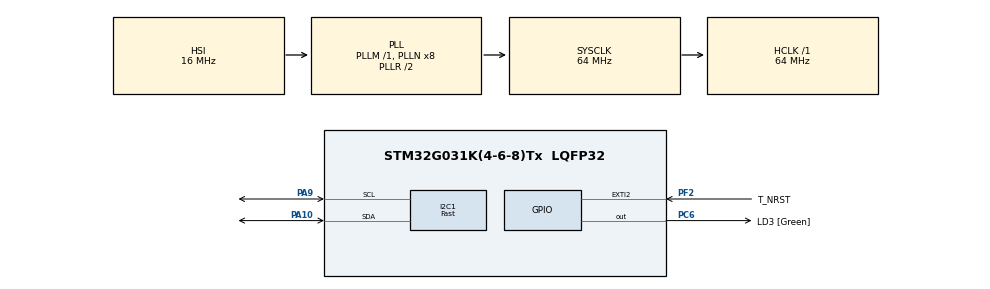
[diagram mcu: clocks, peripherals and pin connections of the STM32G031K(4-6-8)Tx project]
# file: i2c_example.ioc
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I2C1.I2C_Speed_Mode=I2C_Fast
I2C1.OwnAddress=0x45
I2C1.Timing=0x00602173
Mcu.Family=STM32G0
Mcu.Name=STM32G031K(4-6-8)Tx
Mcu.Package=LQFP32
NVIC.I2C1_IRQn=true\:2\:0\:true\:false\:true\:true\:true\:true
PA10.Mode=I2C
PA10.Signal=I2C1_SDA
PA13.GPIO_Label=T_JTMS
PA13.Mode=Serial_Wire
PA13.Signal=SYS_SWDIO
PA14-BOOT0.GPIO_Label=T_JTCK
PA14-BOOT0.Mode=Serial_Wire
PA14-BOOT0.Signal=SYS_SWCLK
PA2.GPIO_Label=T_VCP_TX
PA2.Signal=USART2_TX
PA3.GPIO_Label=T_VCP_RX
PA3.Signal=USART2_RX
PA9.Mode=I2C
PA9.Signal=I2C1_SCL
PC14-OSC32_IN\ (PC14).Mode=LSE-External-Oscillator
PC14-OSC32_IN\ (PC14).Signal=RCC_OSC32_IN
PC15-OSC32_OUT\ (PC15).Mode=LSE-External-Oscillator
PC15-OSC32_OUT\ (PC15).Signal=RCC_OSC32_OUT
PC6.GPIO_Label=LD3 [Green]
PC6.Signal=GPIO_Output
PF2\ -\ NRST.GPIO_Label=T_NRST
PF2\ -\ NRST.Signal=GPXTI2
ProjectManager.HeapSize=0x200
ProjectManager.StackSize=0x400
ProjectManager.TargetToolchain=STM32CubeIDE
RCC.ADCFreq_Value=64000000
RCC.AHBFreq_Value=64000000
RCC.CortexFreq_Value=64000000
RCC.EXTERNAL_CLOCK_VALUE=12288000
RCC.HCLKFreq_Value=64000000
RCC.HSE_VALUE=3000000
RCC.HSI_VALUE=16000000
RCC.SYSCLKFreq_VALUE=64000000
RCC.SYSCLKSource=RCC_SYSCLKSOURCE_PLLCLK
RCC.VCOOutputFreq_Value=128000000
board=NUCLEO-G031K8

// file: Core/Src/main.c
/* USER CODE BEGIN Header */
/**
  ******************************************************************************
  * @file           : main.c
  * @brief          : Main program body
  ******************************************************************************
  * @attention
  *
  * Copyright (c) 2024 STMicroelectronics.
  * All rights reserved.
  *
  * This software is licensed under terms that can be found in the LICENSE file
  * in the root directory of this software component.
  * If no LICENSE file comes with this software, it is provided AS-IS.
  *
  ******************************************************************************
  */
/* USER CODE END Header */
#include "main.h"

/* USER CODE BEGIN Includes */
#include "i2c_slave.h"
/* USER CODE END Includes */

I2C_HandleTypeDef hi2c1;

void SystemClock_Config(void);
static void MX_GPIO_Init(void);
static void MX_I2C1_Init(void);
/* USER CODE BEGIN PFP */
static void led_lights (void);
/* USER CODE END PFP */

int main(void)
{

  /* MCU Configuration--------------------------------------------------------*/

  /* Reset of all peripherals, Initializes the Flash interface and the Systick. */
  HAL_Init();

  /* Configure the system clock */
  SystemClock_Config();

  /* Initialize all configured peripherals */
  MX_GPIO_Init();
  MX_I2C1_Init();
  /* USER CODE BEGIN 2 */
  HAL_I2C_EnableListen_IT (&hi2c1);
  I2C_Setup_Readonly_Register (0, 0x574D44);		// manufacturer ID
  I2C_Setup_Readonly_Register (1, 0x32200001);		// part number
  I2C_Setup_Readonly_Register (2, 0x0001);			// firmware version
  I2C_Setup_Callback_Register (4, led_lights);
  /* USER CODE END 2 */

  /* Infinite loop */
  while (1)
  {

  }
}

void SystemClock_Config(void)
{
  RCC_OscInitTypeDef RCC_OscInitStruct = {0};
  RCC_ClkInitTypeDef RCC_ClkInitStruct = {0};

  /** Configure the main internal regulator output voltage
  */
  HAL_PWREx_ControlVoltageScaling(PWR_REGULATOR_VOLTAGE_SCALE1);

  /** Initializes the RCC Oscillators according to the specified parameters
  * in the RCC_OscInitTypeDef structure.
  */
  RCC_OscInitStruct.OscillatorType = RCC_OSCILLATORTYPE_HSI;
  RCC_OscInitStruct.HSIState = RCC_HSI_ON;
  RCC_OscInitStruct.HSIDiv = RCC_HSI_DIV1;
  RCC_OscInitStruct.HSICalibrationValue = RCC_HSICALIBRATION_DEFAULT;
  RCC_OscInitStruct.PLL.PLLState = RCC_PLL_ON;
  RCC_OscInitStruct.PLL.PLLSource = RCC_PLLSOURCE_HSI;
  RCC_OscInitStruct.PLL.PLLM = RCC_PLLM_DIV1;
  RCC_OscInitStruct.PLL.PLLN = 8;
  RCC_OscInitStruct.PLL.PLLP = RCC_PLLP_DIV2;
  RCC_OscInitStruct.PLL.PLLQ = RCC_PLLQ_DIV2;
  RCC_OscInitStruct.PLL.PLLR = RCC_PLLR_DIV2;
  if (HAL_RCC_OscConfig(&RCC_OscInitStruct) != HAL_OK)
  {
    Error_Handler();
  }

  /** Initializes the CPU, AHB and APB buses clocks
  */
  RCC_ClkInitStruct.ClockType = RCC_CLOCKTYPE_HCLK|RCC_CLOCKTYPE_SYSCLK
                              |RCC_CLOCKTYPE_PCLK1;
  RCC_ClkInitStruct.SYSCLKSource = RCC_SYSCLKSOURCE_PLLCLK;
  RCC_ClkInitStruct.AHBCLKDivider = RCC_SYSCLK_DIV1;
  RCC_ClkInitStruct.APB1CLKDivider = RCC_HCLK_DIV1;

  if (HAL_RCC_ClockConfig(&RCC_ClkInitStruct, FLASH_LATENCY_2) != HAL_OK)
  {
    Error_Handler();
  }
}

static void MX_I2C1_Init(void)
{

  hi2c1.Instance = I2C1;
  hi2c1.Init.Timing = 0x00602173;
  hi2c1.Init.OwnAddress1 = 138;
  hi2c1.Init.AddressingMode = I2C_ADDRESSINGMODE_7BIT;
  hi2c1.Init.DualAddressMode = I2C_DUALADDRESS_DISABLE;
  hi2c1.Init.OwnAddress2 = 0;
  hi2c1.Init.OwnAddress2Masks = I2C_OA2_NOMASK;
  hi2c1.Init.GeneralCallMode = I2C_GENERALCALL_DISABLE;
  hi2c1.Init.NoStretchMode = I2C_NOSTRETCH_DISABLE;
  if (HAL_I2C_Init(&hi2c1) != HAL_OK)
  {
    Error_Handler();
  }

  /** Configure Analogue filter
  */
  if (HAL_I2CEx_ConfigAnalogFilter(&hi2c1, I2C_ANALOGFILTER_ENABLE) != HAL_OK)
  {
    Error_Handler();
  }

  /** Configure Digital filter
  */
  if (HAL_I2CEx_ConfigDigitalFilter(&hi2c1, 0) != HAL_OK)
  {
    Error_Handler();
  }

}

static void MX_GPIO_Init(void)
{
  GPIO_InitTypeDef GPIO_InitStruct = {0};

  /* GPIO Ports Clock Enable */
  __HAL_RCC_GPIOC_CLK_ENABLE();
  __HAL_RCC_GPIOF_CLK_ENABLE();
  __HAL_RCC_GPIOA_CLK_ENABLE();

  /*Configure GPIO pin Output Level */
  HAL_GPIO_WritePin(LD3_GPIO_Port, LD3_Pin, GPIO_PIN_RESET);

  /*Configure GPIO pin : T_NRST_Pin */
  GPIO_InitStruct.Pin = T_NRST_Pin;
  GPIO_InitStruct.Mode = GPIO_MODE_IT_RISING;
  GPIO_InitStruct.Pull = GPIO_NOPULL;
  HAL_GPIO_Init(T_NRST_GPIO_Port, &GPIO_InitStruct);

  /*Configure GPIO pins : T_VCP_TX_Pin T_VCP_RX_Pin */
  GPIO_InitStruct.Pin = T_VCP_TX_Pin|T_VCP_RX_Pin;
  GPIO_InitStruct.Mode = GPIO_MODE_AF_PP;
  GPIO_InitStruct.Pull = GPIO_NOPULL;
  GPIO_InitStruct.Speed = GPIO_SPEED_FREQ_LOW;
  GPIO_InitStruct.Alternate = GPIO_AF1_USART2;
  HAL_GPIO_Init(GPIOA, &GPIO_InitStruct);

  /*Configure GPIO pin : LD3_Pin */
  GPIO_InitStruct.Pin = LD3_Pin;
  GPIO_InitStruct.Mode = GPIO_MODE_OUTPUT_PP;
  GPIO_InitStruct.Pull = GPIO_NOPULL;
  GPIO_InitStruct.Speed = GPIO_SPEED_FREQ_LOW;
  HAL_GPIO_Init(LD3_GPIO_Port, &GPIO_InitStruct);

}

/* USER CODE BEGIN 4 */
static void led_lights (void)
{
	HAL_GPIO_WritePin (LD3_GPIO_Port, LD3_Pin, REGISTER(4) & 1);
}

/* USER CODE END 4 */

void Error_Handler(void)
{
  __disable_irq();
  while (1)
  {
  }
}
